# STM32H7R register map
File version: 1.3
CPU: CM7 r0p1, little endian, MPU, FPU, 4 interrupt priority bits
Registers are 32-bit, read-write, reset 0x0 unless marked. A register's access mark holds for its fields unless they carry their own. Offsets are from the block's base; [hi:lo] are bit positions; {n}, {i} and the like mark numbered series.

## GFXTIM — Graphic timer
Base 0x50004000
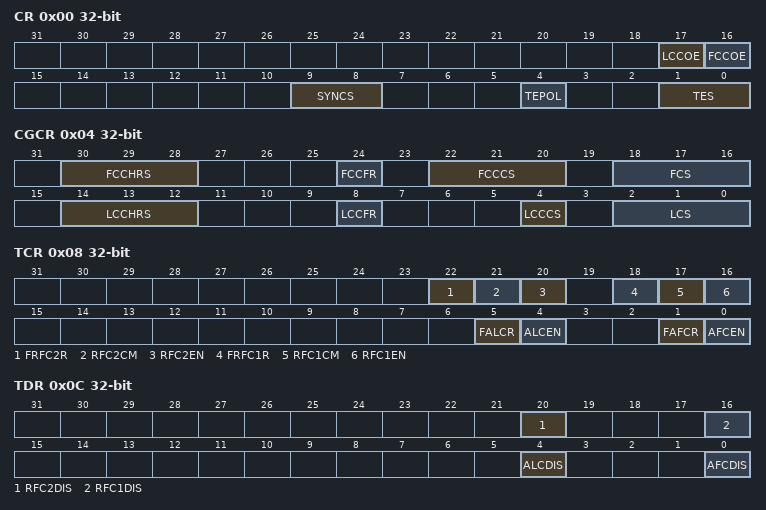
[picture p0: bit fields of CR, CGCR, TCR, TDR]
0x00 CR — GFXTIM configuration register
  [17] LCCOE — line-clock calibration output enable This bit enables the line-clock output.
  [16] FCCOE — frame-clock calibration output enable This bit enables the frame-clock output.
  [9:8] SYNCS — synchronization source This field selects the synchronization signals (HSYNC and VSYNC) sources.
  [4] TEPOL — tearing--effect polarity This bit selects the tearing-effect polarity.
  [1:0] TES — tearing source This field selects the tearing-effect source.
0x04 CGCR access per field — GFXTIM clock generator configuration register
  [30:28] FCCHRS rw — frame- -clock counter hardware reload source This field configures the hardware reload source for the frame- -clock counter.
  [24] FCCFR wo — frame clock counter force reload This bit forces frame clock counter reload
  [22:20] FCCCS rw — frame clock counter clock source This field configures the clock source for the frame clock counter.
  [18:16] FCS rw — frame clock source This field configures the frame clock source
  [14:12] LCCHRS rw — line clock counter hardware reload source This field configures the hardware reload source for the line clock counter.
  [8] LCCFR wo — line clock counter force reload This bit forces line clock counter reload.
  [4] LCCCS rw — line clock counter clock source This bit configures the clock source for the line clock counter.
  [2:0] LCS rw — line clock source This field configures the line clock source.
0x08 TCR access per field — GFXTIM timers configuration register
  [22] FRFC2R wo — force relative frame counter 2 reload This bit forces the reload of the relative frame counter 2.
  [21] RFC2CM rw — relative frame counter 2 continuous mode This bit enables the continuous mode of the relative frame counter 2.
  [20] RFC2EN wo — relative frame counter 2 enable This bit enables the relative frame counter 2.
  [18] FRFC1R wo — force relative frame counter 1 reload This bit forces the reload of the relative frame counter 1.
  [17] RFC1CM rw — relative frame counter 1 continuous mode This bit enables the continuous mode of the relative frame counter 1.
  [16] RFC1EN wo — relative frame counter 1 enable This bit enables the relative frame counter 1.
  [5] FALCR wo — force absolute line counter reset This bit forces the reset of the absolute line counter.
  [4] ALCEN wo — absolute line counter enable This bit enables the absolute line counter.
  [1] FAFCR wo — force absolute frame counter reset This bit forces the reset of the absolute frame counter.
  [0] AFCEN wo — absolute frame counter enable This bit enables the absolute frame counter.
0x0C TDR wo — GFXTIM timers disable register
  [20] RFC2DIS — relative frame counter 2 disable This bit disables the relative frame counter 2.
  [16] RFC1DIS — relative frame counter 1 disable This bit disables the relative frame counter 1.
  [4] ALCDIS — absolute line counter disable This bit disables the absolute line counter.
  [0] AFCDIS — absolute frame counter disable This bit disables the absolute frame counter.
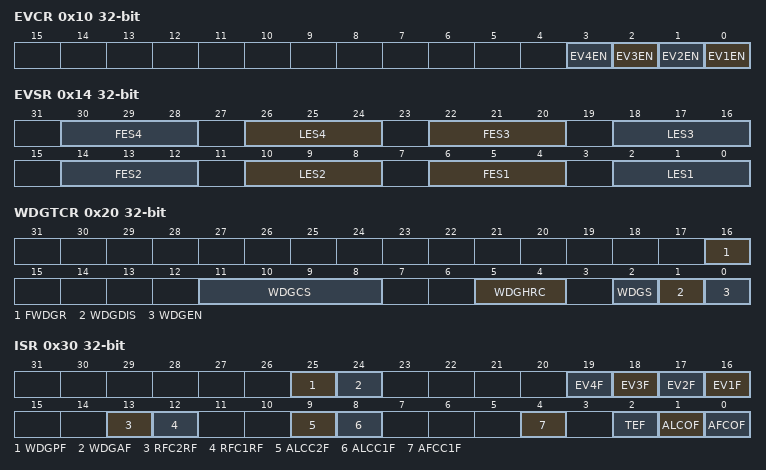
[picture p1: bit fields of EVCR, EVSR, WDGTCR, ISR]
0x10 EVCR — GFXTIM events control register
  [n-1] EV{n}EN (n=1..4) — event {n} enable This bit enables the complex event {n} generation.
0x14 EVSR — GFXTIM events selection register
  [8n-2:8n-4] FES{n} (n=1..4) — frame-event selection {n} This field defines the frame-event selection for complex event {n} generation. others: reserved
  [26:24] LES4 — line-event selection 4 This field defines the line-event selection for complex event 4 generation. others: Reserved
  [18:16] LES3 — line-event selection 3 This field defines the line-event selection for complex event 3 generation. others: reserved
  [10:8] LES2 — line-event selection 2 This field defines the line-event selection for complex event 2 generation. others: reserved
  [2:0] LES1 — line-event selection 1 This field defines the line-event selection for complex event 1 generation. others: reserved
0x20 WDGTCR access per field — GFXTIM watchdog timer configuration register
  [16] FWDGR wo — force watchdog reload This bit forces the reload of the graphic watchdog.
  [11:8] WDGCS rw — watchdog clock source This field selects the watchdog clock source. others: reserved
  [5:4] WDGHRC rw — watchdog hardware reload configuration This field configures the watchdog hardware reload.
  [2] WDGS ro — watchdog status This bit returns the status of the graphic watchdog.
  [1] WDGDIS wo — watchdog disable This bit disables the graphic watchdog.
  [0] WDGEN wo — watchdog enable This bit enables the graphic watchdog.
0x30 ISR ro — GFXTIM interrupt status register
  [25] WDGPF — watchdog pre-alarm flag This bit indicates that a graphic watchdog pre-alarm occurred.
  [24] WDGAF — watchdog alarm flag This bit indicates that a graphic watchdog alarm occurred.
  [n+15] EV{n}F (n=1..4) — event {n} flag This bit indicates a complex event {n} occurred.
  [13] RFC2RF — relative frame counter 2 reload flag This bit indicates relative frame counter 2 has been reloaded.
  [12] RFC1RF — relative frame counter 1 reload flag This bit indicates relative frame counter 1 has been reloaded.
  [9] ALCC2F — absolute line counter compare 2 flag This bit indicates match on compare 2 of the absolute line counter.
  [8] ALCC1F — absolute line counter compare 1 flag This bit indicates match on compare 1 of the absolute line counter.
  [4] AFCC1F — absolute frame counter compare 1 flag This bit indicates match on compare 1 of the absolute frame counter.
  [2] TEF — tearing-effect flag This bit indicates a tearing effect event occurred.
  [1] ALCOF — absolute line counter overflow flag This bit indicates an overflow occurred on the absolute line counter.
  [0] AFCOF — absolute frame counter overflow flag This bit indicates an overflow occurred on the absolute frame counter.
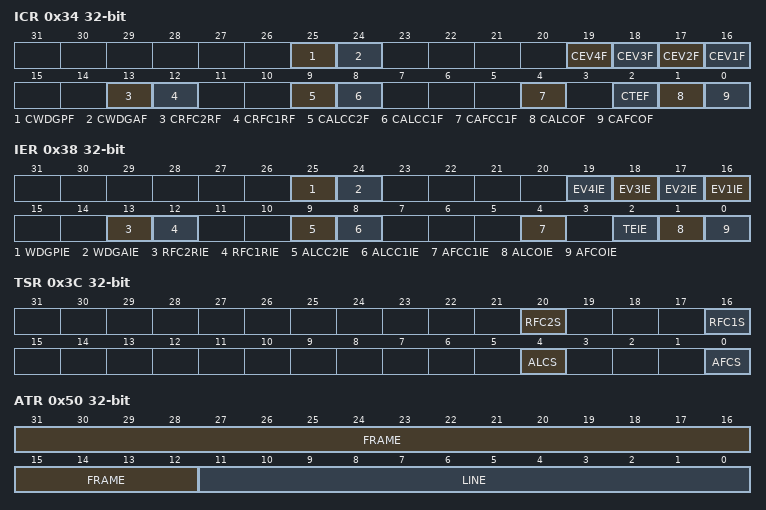
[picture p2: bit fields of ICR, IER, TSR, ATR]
0x34 ICR wo — GFXTIM interrupt clear register
  [25] CWDGPF — clear watchdog pre-alarm flag This bit clears WDGPF in GXFXTIM_ISR.
  [24] CWDGAF — clear watchdog alarm flag This bit clears WDGAF in GXFXTIM_ISR.
  [19] CEV4F — clear event 4 flag This bit clears EV4F in GXFXTIM_ISR.
  [18] CEV3F — clear event 3 flag This bit clears EV3F in GXFXTIM_ISR.
  [17] CEV2F — clear event 2 flag This bit clears EV2F in GXFXTIM_ISR.
  [16] CEV1F — clear event 1 flag This bit EV1F in GXFXTIM_ISR.
  [13] CRFC2RF — clear relative frame counter 2 reload flag This bit clears RFC2RF in GXFXTIM_ISR.
  [12] CRFC1RF — clear relative frame counter 1 reload flag This bit clears RFC1RF in GXTIM_ISR.
  [9] CALCC2F — clear absolute line counter compare 2 flag This bit clears ALCC2F in GXTIM_ISR.
  [8] CALCC1F — clear absolute line counter compare 1 flag This bit clears ALCC1F in GXTIM_ISR.
  [4] CAFCC1F — clear absolute frame counter compare 1 flag This bit clears AFCC1F in GXTIM_ISR.
  [2] CTEF — clear tearing-effect flag This bit clears TEF in GXTIM_ISR.
  [1] CALCOF — clear absolute line counter overflow flag This bit clears ALCOF in GXTIM_ISR.
  [0] CAFCOF — clear absolute frame counter overflow flag This bit clears AFCOF in GXTIM_ISR.
0x38 IER — GFXTIM interrupt enable register
  [25] WDGPIE — watchdog pre-alarm interrupt enable This bit enables the watchdog pre-alarm interrupt generation.
  [24] WDGAIE — watchdog alarm interrupt enable This bit enables the watchdog alarm interrupt generation.
  [n+15] EV{n}IE (n=1..4) — event {n} interrupt enable This bit enables the complex event {n} interrupt generation.
  [13] RFC2RIE — relative frame counter 2 reload interrupt enable This bit enables the relative frame counter 2 reload interrupt generation.
  [12] RFC1RIE — relative frame counter 1 reload interrupt enable This bit enables the relative frame counter 1 reload interrupt generation.
  [9] ALCC2IE — absolute line counter compare 2 interrupt enable This bit enables the absolute line counter compare 2 interrupt generation.
  [8] ALCC1IE — absolute line counter compare 1 interrupt enable This bit enables the absolute line counter compare 1 interrupt generation.
  [4] AFCC1IE — absolute frame counter compare 1 interrupt enable This bit enables the absolute frame counter compare interrupt generation.
  [2] TEIE — tearing-effect interrupt enable This bit enables the Tearing Effect interrupt generation.
  [1] ALCOIE — absolute line counter overflow interrupt enable This bit enables the absolute line counter overflow interrupt generation.
  [0] AFCOIE — absolute frame counter overflow interrupt enable This bit enables the absolute frame counter overflow interrupt generation.
0x3C TSR ro — GFXTIM timers status register
  [20] RFC2S — relative frame counter 2 status This bit returns the status of the relative frame counter 2.
  [16] RFC1S — relative frame counter 1 status This bit returns the status of the relative frame counter 1.
  [4] ALCS — absolute line counter status This bit returns the status of the absolute line counter.
  [0] AFCS — absolute frame counter status This bit returns the status of the absolute frame counter.
0x40 LCCRR — GFXTIM line clock counter reload register
  [21:0] RELOAD — reload value Reload value of the line clock counter.
0x44 FCCRR — GFXTIM frame clock counter reload register
  [11:0] RELOAD — reload value Reload value of the frame clock counter.
0x50 ATR ro — GFXTIM absolute time register
  [31:12] FRAME — fame number Current value of the absolute frame counter.
  [11:0] LINE — line number Current value of the absolute line counter.
0x54 AFCR — GFXTIM absolute frame counter register
  [19:0] FRAME — frame number Current value of the absolute frame counter. Note: This field can only be written when the absolute frame counter is disabled.
0x58 ALCR — GFXTIM absolute line counter register
  [11:0] LINE — line number Current value of the absolute line counter. Note: This field can only be written when the absolute frame counter is disabled.
0x60 AFCC1R — GFXTIM absolute frame counter compare 1 register
  [19:0] FRAME — frame number Compare 1 value for the absolute frame counter.
0x70 ALCC1R — GFXTIM absolute line counter compare 1 register
  [11:0] LINE — line number Compare value 1 for the absolute line counter.
0x74 ALCC2R — GFXTIM absolute line counter compare 2 register
  [11:0] LINE — line number Compare value 2 for the absolute line counter.
0x80 RFC1R ro — GFXTIM relative frame counter 1 register
  [11:0] FRAME — frame number Current value of the relative frame counter 1.
0x84 RFC1RR — GFXTIM relative frame counter 1 reload register
  [11:0] FRAME — frame reload value Reload value for the relative frame counter 1.
0x88 RFC2R ro — GFXTIM relative frame counter 2 register
  [11:0] FRAME — frame number Current value of the relative frame counter 2.
0x8C RFC2RR — GFXTIM relative frame counter 2 reload register
  [11:0] FRAME — frame reload value Reload value for the relative frame counter 2.
0xA0 WDGCR ro — GFXTIM watchdog counter register
  [15:0] VALUE — value Current value of the watchdog counter.
0xA4 WDGRR — GFXTIM watchdog reload register
  [15:0] RELOAD — reload value Reload value of the watchdog counter.
0xA8 WDGPAR — GFXTIM watchdog pre-alarm register
  [15:0] PREALARM — pre-alarm value Pre-alarm value of the watchdog counter.
